# MB9BFD1xS register map
File version: 1.8
CPU: 
Registers are 32-bit, read-write, reset 0x0 unless marked. A register's access mark holds for its fields unless they carry their own. Offsets are from the block's base; [hi:lo] are bit positions; {n}, {i} and the like mark numbered series.

## LVD — Low-voltage Detection
Base 0x40035000
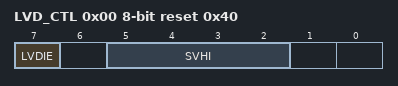
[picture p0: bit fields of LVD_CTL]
0x00 LVD_CTL 8-bit reset 0x40 — Low-voltage Detection Voltage Control Register
  [7] LVDIE — Low-voltage detection interrupt enable bit
  [5:2] SVHI — Low-voltage detection interrupt voltage setting bits
0x04 LVD_STR 8-bit ro — Low-voltage Detection Interrupt Register
  [7] LVDIR — Low-voltage detection interrupt bit
0x08 LVD_CLR 8-bit reset 0x80 — Low-voltage Detection Interrupt Clear Register
  [7] LVDCL — Low-voltage detection interrupt clear bit
0x0C LVD_RLR reset 0x1 — Low-voltage Detection Voltage Protection Register
  [31:0] LVDLCK — Low-voltage Detection Voltage Control Register protection bits
0x10 LVD_STR2 8-bit ro reset 0x40 — Low-voltage Detection Circuit Status Register
  [7] LVDIRDY — Low-voltage detection interrupt status flag

## MFS_NFC — I2C Auxiliary Noise Filter Setting Register
Base 0x40038800
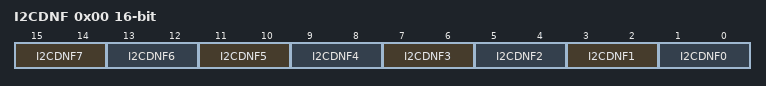
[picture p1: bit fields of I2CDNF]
0x00 I2CDNF 16-bit — I2C Auxiliary Noise Filter Setting Register
  [15:14] I2CDNF7 — Auxiliary noise filter additional step select bits for I2C ch.7
  [13:12] I2CDNF6 — Auxiliary noise filter additional step select bits for I2C ch.6
  [11:10] I2CDNF5 — Auxiliary noise filter additional step select bits for I2C ch.5
  [9:8] I2CDNF4 — Auxiliary noise filter additional step select bits for I2C ch.4
  [7:6] I2CDNF3 — Auxiliary noise filter additional step select bits for I2C ch.3
  [5:4] I2CDNF2 — Auxiliary noise filter additional step select bits for I2C ch.2
  [3:2] I2CDNF1 — Auxiliary noise filter additional step select bits for I2C ch.1
  [1:0] I2CDNF0 — Auxiliary noise filter additional step select bits for I2C ch.0

## CRC — CRC Registers
Base 0x40039000
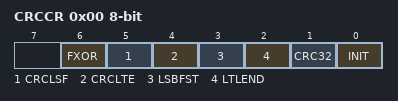
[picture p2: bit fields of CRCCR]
0x00 CRCCR 8-bit — CRC Control Register
  [6] FXOR — Initialization bit
  [5] CRCLSF — Final XOR control bit
  [4] CRCLTE — CRC result bit-order setting bit
  [3] LSBFST — CRC result byte-order setting bit
  [2] LTLEND — Bit-order setting bit
  [1] CRC32 — Byte-order setting bit
  [0] INIT — CRC mode selection bit
0x04 CRCINIT reset 0xFFFFFFFF — Initial Value Register
  [31:0] D — Initial value
0x08 CRCIN — Input Data Register
  [31:0] D — Input data
0x0C CRCR ro reset 0xFFFFFFFF — CRC Register
  [31:0] D — CRC Data

## EXBUS — External Bus Interface
Base 0x4003F000
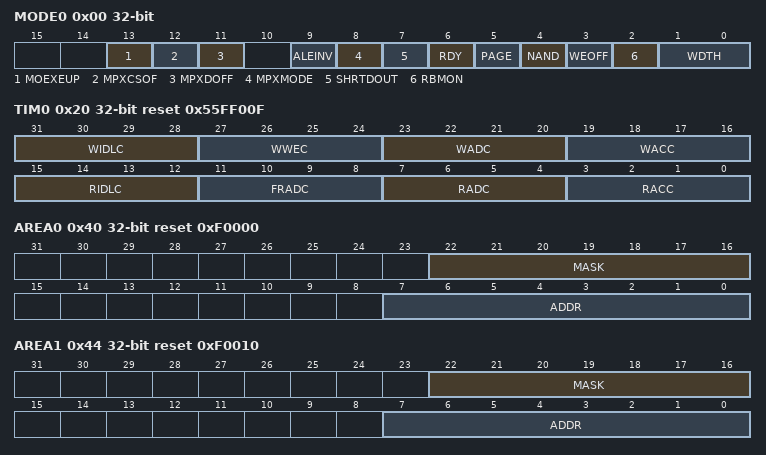
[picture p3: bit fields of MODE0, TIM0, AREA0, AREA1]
0x00 MODE0 — Mode Register 0
  [13] MOEXEUP — select how to set the MOEX width
  [12] MPXCSOF — select a CS assertion from the start of accessing to the end of address output
  [11] MPXDOFF — select whether or not the address is output to the data lines in multiplex mode
  [9] ALEINV — set up the polarity of the ALE signal
  [8] MPXMODE — select operation bus mode
  [7] SHRTDOUT — select to which idle cycle the write data output is extended
  [6] RDY — control the external RDY function
  [5] PAGE — NOR Flash memory page access mode
  [4] NAND — NAND Flash memory mode
  [3] WEOFF — disable the write enable signal (MWEX) operation
  [2] RBMON — Read Byte Mask ON
  [1:0] WDTH — specify Data Width
{0x0+4i} MODE{i} reset not defined (i=1..7) — Mode Register {i}
0x20 TIM0 reset 0x55FF00F — Timing Register 0
  [31:28] WIDLC — Write Idle Cycle
  [27:24] WWEC — Write Enable Cycle
  [23:20] WADC — Write Address Setup cycle
  [19:16] WACC — Write Access Cycle
  [15:12] RIDLC — Read Idle Cycle
  [11:8] FRADC — First Read Address Cycle
  [7:4] RADC — Read Address Setup cycle
  [3:0] RACC — Read Access Cycle
{0x20+4i} TIM{i} reset not defined (i=1..7) — Timing Register {i}
0x40 AREA0 reset 0xF0000 — Area Register 0
  [22:16] MASK — address mask
  [7:0] ADDR — Address
0x44 AREA1 reset 0xF0010 — Area Register 1
  [22:16] MASK — address mask
  [7:0] ADDR — Address
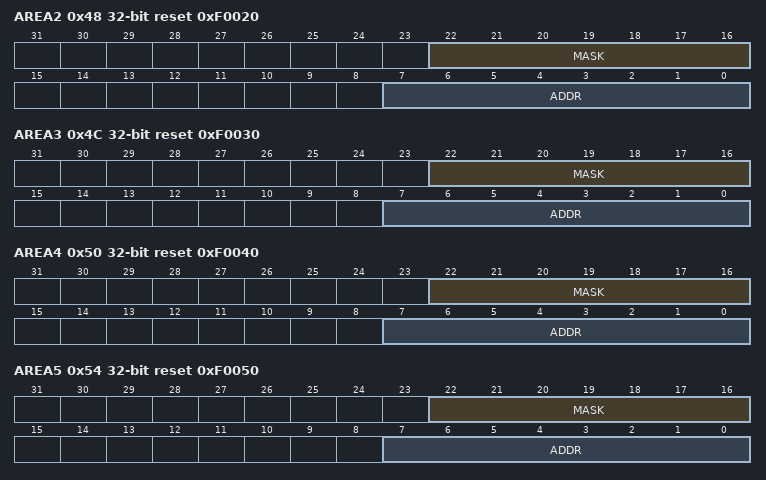
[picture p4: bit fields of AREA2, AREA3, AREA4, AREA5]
0x48 AREA2 reset 0xF0020 — Area Register 2
  [22:16] MASK — address mask
  [7:0] ADDR — Address
0x4C AREA3 reset 0xF0030 — Area Register 3
  [22:16] MASK — address mask
  [7:0] ADDR — Address
0x50 AREA4 reset 0xF0040 — Area Register 4
  [22:16] MASK — address mask
  [7:0] ADDR — Address
0x54 AREA5 reset 0xF0050 — Area Register 5
  [22:16] MASK — address mask
  [7:0] ADDR — Address
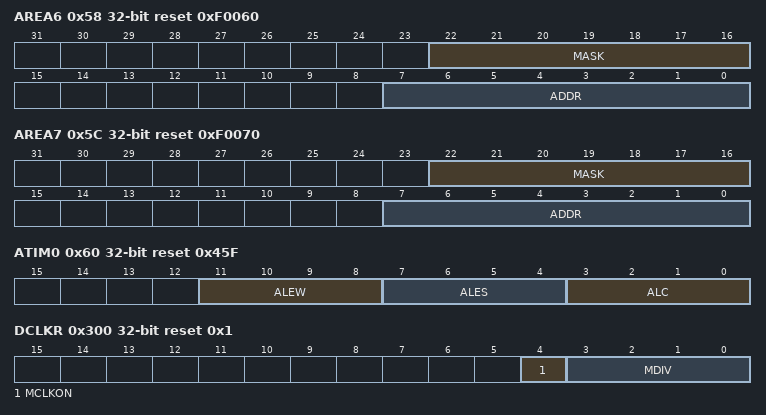
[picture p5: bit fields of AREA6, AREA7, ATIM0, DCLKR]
0x58 AREA6 reset 0xF0060 — Area Register 6
  [22:16] MASK — address mask
  [7:0] ADDR — Address
0x5C AREA7 reset 0xF0070 — Area Register 7
  [22:16] MASK — address mask
  [7:0] ADDR — Address
0x60 ATIM0 reset 0x45F — ALE Timing Register 0
  [11:8] ALEW — Address Latch Enable Width
  [7:4] ALES — Address Latch Enable Setup cycle
  [3:0] ALC — Address Latch Cycle
{0x60+4i} ATIM{i} reset not defined (i=1..7) — ALE Timing Register {i}
0x300 DCLKR reset 0x1 (reset mask 0xF) — Division Clock Register
  [4] MCLKON
  [3:0] MDIV — MCLK Division Ratio Setup
